# EFM32ZG1xx_2xx register map
File version: 2.7.3
CPU: CM0PLUS r0p1, little endian, no MPU, no FPU, 3 interrupt priority bits
Registers are 32-bit, read-write, reset 0x0 unless marked. A register's access mark holds for its fields unless they carry their own. Offsets are from the block's base; [hi:lo] are bit positions; {n}, {i} and the like mark numbered series.

## DMA
Base 0x400C2000
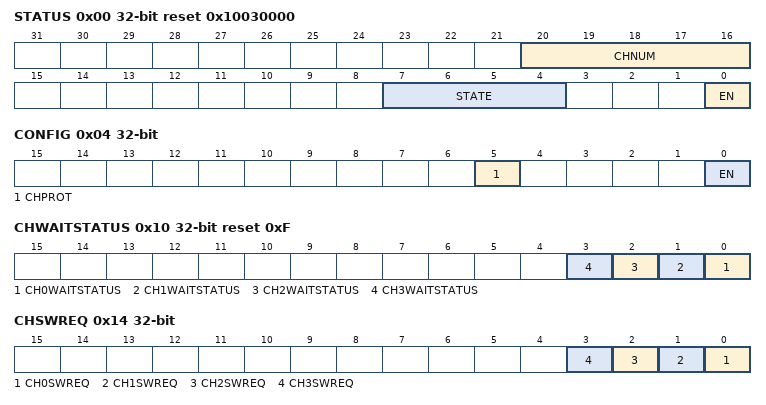
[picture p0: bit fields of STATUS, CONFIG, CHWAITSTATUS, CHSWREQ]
0x00 STATUS ro reset 0x10030000 — DMA Status Registers
  [20:16] CHNUM — Channel Number
  [7:4] STATE — Control Current State
    0=IDLE; 1=RDCHCTRLDATA (Reading channel controller data); 2=RDSRCENDPTR (Reading source data end pointer); 3=RDDSTENDPTR (Reading destination data end pointer); 4=RDSRCDATA (Reading source data); 5=WRDSTDATA (Writing destination data); 6=WAITREQCLR (Waiting for DMA request to clear); 7=WRCHCTRLDATA (Writing channel controller data); 8=STALLED; 9=DONE; 10=PERSCATTRANS (Peripheral scatter-gather transition)
  [0] EN — DMA Enable Status
0x04 CONFIG wo — DMA Configuration Register
  [5] CHPROT — Channel Protection Control
  [0] EN — Enable DMA
0x08 CTRLBASE — Channel Control Data Base Pointer Register
  [31:0] CTRLBASE — Channel Control Data Base Pointer
0x0C ALTCTRLBASE ro reset 0x40 — Channel Alternate Control Data Base Pointer Register
  [31:0] ALTCTRLBASE — Channel Alternate Control Data Base Pointer
0x10 CHWAITSTATUS ro reset 0xF — Channel Wait on Request Status Register
  [n] CH{n}WAITSTATUS (n=0..3) — Channel {n} Wait on Request Status
0x14 CHSWREQ wo — Channel Software Request Register
  [n] CH{n}SWREQ (n=0..3) — Channel {n} Software Request
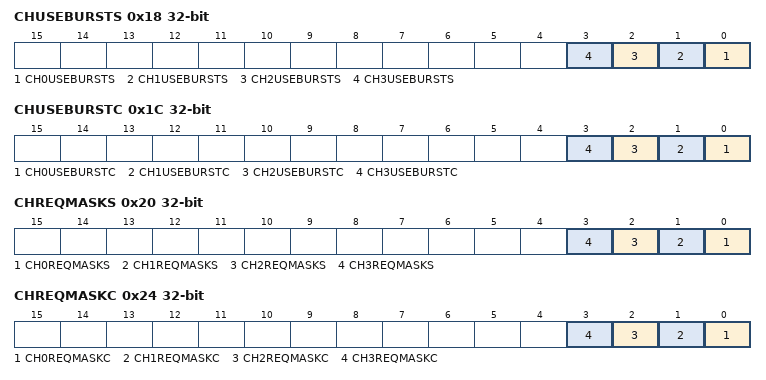
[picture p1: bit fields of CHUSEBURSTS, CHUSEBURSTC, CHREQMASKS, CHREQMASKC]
0x18 CHUSEBURSTS — Channel Useburst Set Register
  [n] CH{n}USEBURSTS (n=0..3) — Channel {n} Useburst Set
0x1C CHUSEBURSTC wo — Channel Useburst Clear Register
  [n] CH{n}USEBURSTC (n=0..3) — Channel {n} Useburst Clear
0x20 CHREQMASKS wo — Channel Request Mask Set Register
  [n] CH{n}REQMASKS (n=0..3) — Channel {n} Request Mask Set
0x24 CHREQMASKC wo — Channel Request Mask Clear Register
  [n] CH{n}REQMASKC (n=0..3) — Channel {n} Request Mask Clear
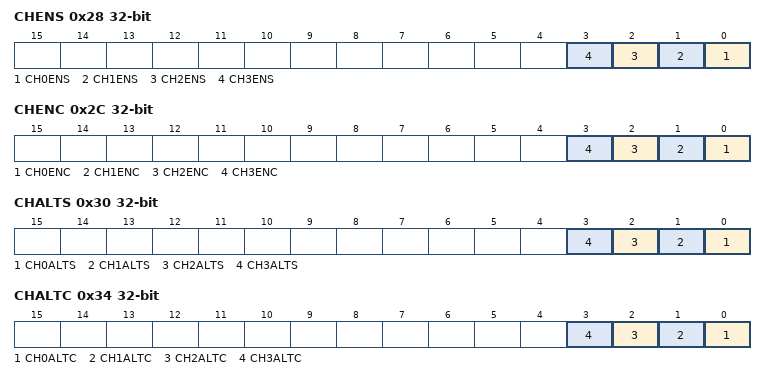
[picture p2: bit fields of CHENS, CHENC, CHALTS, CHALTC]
0x28 CHENS wo — Channel Enable Set Register
  [n] CH{n}ENS (n=0..3) — Channel {n} Enable Set
0x2C CHENC wo — Channel Enable Clear Register
  [n] CH{n}ENC (n=0..3) — Channel {n} Enable Clear
0x30 CHALTS wo — Channel Alternate Set Register
  [n] CH{n}ALTS (n=0..3) — Channel {n} Alternate Structure Set
0x34 CHALTC wo — Channel Alternate Clear Register
  [n] CH{n}ALTC (n=0..3) — Channel {n} Alternate Clear
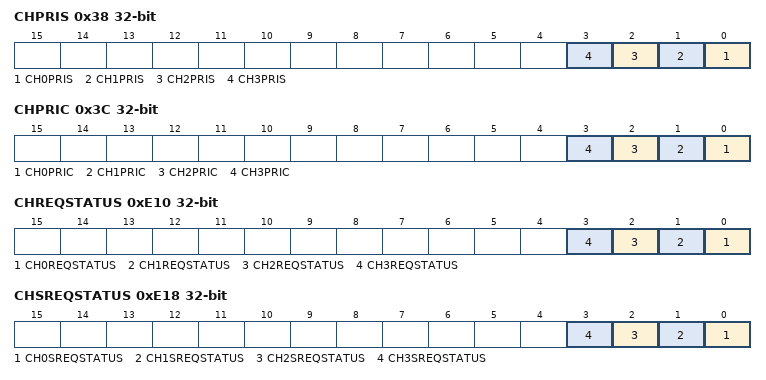
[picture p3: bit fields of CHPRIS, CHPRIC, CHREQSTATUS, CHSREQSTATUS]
0x38 CHPRIS wo — Channel Priority Set Register
  [n] CH{n}PRIS (n=0..3) — Channel {n} High Priority Set
0x3C CHPRIC wo — Channel Priority Clear Register
  [n] CH{n}PRIC (n=0..3) — Channel {n} High Priority Clear
0x4C ERRORC — Bus Error Clear Register
  [0] ERRORC — Bus Error Clear
0xE10 CHREQSTATUS ro — Channel Request Status
  [n] CH{n}REQSTATUS (n=0..3) — Channel {n} Request Status
0xE18 CHSREQSTATUS ro — Channel Single Request Status
  [n] CH{n}SREQSTATUS (n=0..3) — Channel {n} Single Request Status
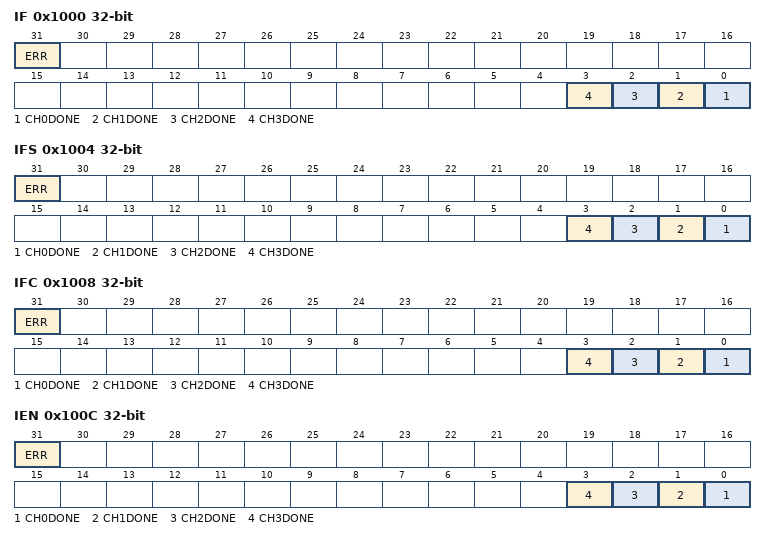
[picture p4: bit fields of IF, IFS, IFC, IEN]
0x1000 IF ro — Interrupt Flag Register
  [31] ERR — DMA Error Interrupt Flag
  [n] CH{n}DONE (n=0..3) — DMA Channel {n} Complete Interrupt Flag
0x1004 IFS wo — Interrupt Flag Set Register
  [31] ERR — DMA Error Interrupt Flag Set
  [n] CH{n}DONE (n=0..3) — DMA Channel {n} Complete Interrupt Flag Set
0x1008 IFC wo — Interrupt Flag Clear Register
  [31] ERR — DMA Error Interrupt Flag Clear
  [n] CH{n}DONE (n=0..3) — DMA Channel {n} Complete Interrupt Flag Clear
0x100C IEN — Interrupt Enable register
  [31] ERR — DMA Error Interrupt Flag Enable
  [n] CH{n}DONE (n=0..3) — DMA Channel {n} Complete Interrupt Enable
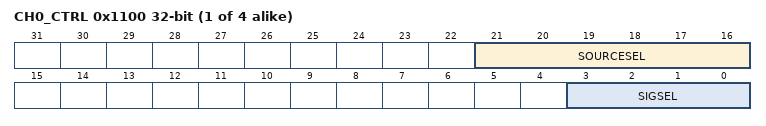
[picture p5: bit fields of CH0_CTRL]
{0x1100+4i} CH{i}_CTRL (i=0..3) — Channel Control Register
  [21:16] SOURCESEL — Source Select
    0=NONE (No source selected); 8=ADC0 (Analog to Digital Converter 0); 13=USART1 (Universal Synchronous/Asynchronous Receiver/Transmitter 1); 16=LEUART0 (Low Energy UART 0); 20=I2C0; 24=TIMER0; 25=TIMER1; 48=MSC; 49=AES (Advanced Encryption Standard Accelerator)
  [3:0] SIGSEL — Signal Select

## MSC
Base 0x400C0000
0x00 CTRL reset 0x1 — Memory System Control Register
  [0] BUSFAULT — Bus Fault Response Enable
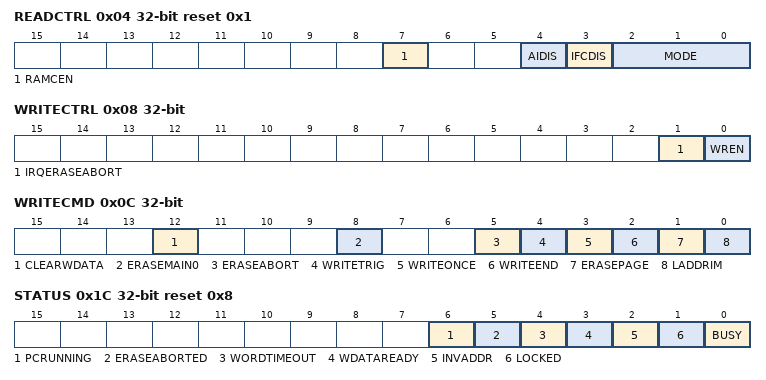
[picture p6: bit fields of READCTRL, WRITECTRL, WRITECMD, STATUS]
0x04 READCTRL reset 0x1 — Read Control Register
  [7] RAMCEN — RAM Cache Enable
  [4] AIDIS — Automatic Invalidate Disable
  [3] IFCDIS — Internal Flash Cache Disable
  [2:0] MODE — Read Mode
    0=WS0 (Zero wait-states inserted in fetch or read transfers.); 1=WS1 (One wait-state inserted for each fetch or read transfer. This mode is required for a core frequency above 16 MHz.)
0x08 WRITECTRL — Write Control Register
  [1] IRQERASEABORT — Abort Page Erase on Interrupt
  [0] WREN — Enable Write/Erase Controller
0x0C WRITECMD wo — Write Command Register
  [12] CLEARWDATA — Clear WDATA state
  [8] ERASEMAIN0 — Mass erase region 0
  [5] ERASEABORT — Abort erase sequence
  [4] WRITETRIG — Word Write Sequence Trigger
  [3] WRITEONCE — Word Write-Once Trigger
  [2] WRITEEND — End Write Mode
  [1] ERASEPAGE
  [0] LADDRIM — Load MSC_ADDRB into ADDR
0x10 ADDRB — Page Erase/Write Address Buffer
  [31:0] ADDRB — Page Erase or Write Address Buffer
0x18 WDATA — Write Data Register
  [31:0] WDATA — Write Data
0x1C STATUS ro reset 0x8
  [6] PCRUNNING — Performance Counters Running
  [5] ERASEABORTED — The Current Flash Erase Operation Aborted
  [4] WORDTIMEOUT — Flash Write Word Timeout
  [3] WDATAREADY — WDATA Write Ready
  [2] INVADDR — Invalid Write Address or Erase Page
  [1] LOCKED — Access Locked
  [0] BUSY — Erase/Write Busy
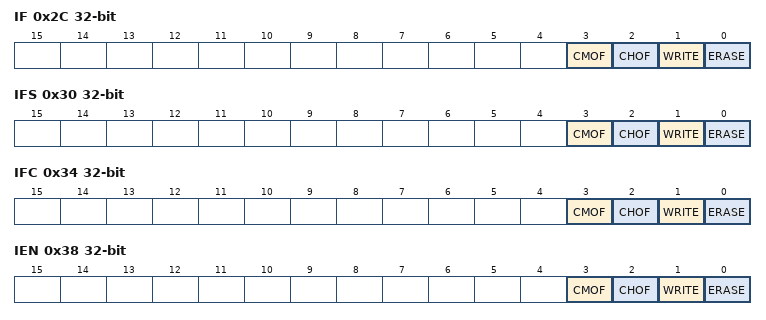
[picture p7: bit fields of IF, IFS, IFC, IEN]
0x2C IF ro — Interrupt Flag Register
  [3] CMOF — Cache Misses Overflow Interrupt Flag
  [2] CHOF — Cache Hits Overflow Interrupt Flag
  [1] WRITE — Write Done Interrupt Read Flag
  [0] ERASE — Erase Done Interrupt Read Flag
0x30 IFS wo — Interrupt Flag Set Register
  [3] CMOF — Cache Misses Overflow Interrupt Set
  [2] CHOF — Cache Hits Overflow Interrupt Set
  [1] WRITE — Write Done Interrupt Set
  [0] ERASE — Erase Done Interrupt Set
0x34 IFC wo — Interrupt Flag Clear Register
  [3] CMOF — Cache Misses Overflow Interrupt Clear
  [2] CHOF — Cache Hits Overflow Interrupt Clear
  [1] WRITE — Write Done Interrupt Clear
  [0] ERASE — Erase Done Interrupt Clear
0x38 IEN — Interrupt Enable Register
  [3] CMOF — Cache Misses Overflow Interrupt Enable
  [2] CHOF — Cache Hits Overflow Interrupt Enable
  [1] WRITE — Write Done Interrupt Enable
  [0] ERASE — Erase Done Interrupt Enable
0x3C LOCK — Configuration Lock Register
  [15:0] LOCKKEY — Configuration Lock
    0=UNLOCKED; 1=LOCKED
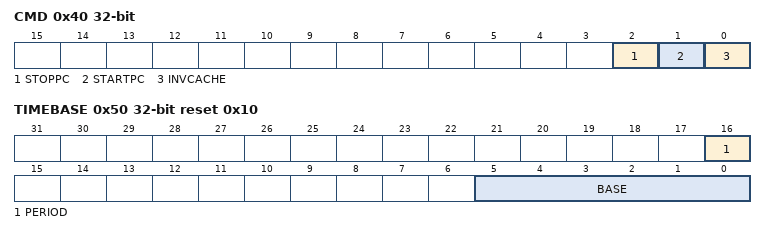
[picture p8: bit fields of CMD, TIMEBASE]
0x40 CMD wo — Command Register
  [2] STOPPC — Stop Performance Counters
  [1] STARTPC — Start Performance Counters
  [0] INVCACHE — Invalidate Instruction Cache
0x44 CACHEHITS ro — Cache Hits Performance Counter
  [19:0] CACHEHITS — Cache hits since last performance counter start command.
0x48 CACHEMISSES ro — Cache Misses Performance Counter
  [19:0] CACHEMISSES — Cache misses since last performance counter start command.
0x50 TIMEBASE reset 0x10 — Flash Write and Erase Timebase
  [16] PERIOD — Sets the timebase period
  [5:0] BASE — Timebase used by MSC to time flash writes and erases
0x54 MASSLOCK reset 0x1 — Mass Erase Lock Register
  [15:0] LOCKKEY — Mass Erase Lock
    0=UNLOCKED (Mass erase unlocked.); 1=LOCKED (Mass erase locked.)
0x58 IRQLATENCY
  [7:0] IRQLATENCY

## Notices in the file
# License
Copyright 2020 Silicon Laboratories Inc. www.silabs.com
SPDX-License-Identifier: Zlib
The licensor of this software is Silicon Laboratories Inc.
This software is provided 'as-is', without any express or implied
warranty. In no event will the authors be held liable for any damages
arising from the use of this software.
Permission is granted to anyone to use this software for any purpose,
including commercial applications, and to alter it and redistribute it
freely, subject to the following restrictions:
1. The origin of this software must not be misrepresented; you must not
claim that you wrote the original software. If you use this software
in a product, an acknowledgment in the product documentation would be
appreciated but is not required.
2. Altered source versions must be plainly marked as such, and must not be
misrepresented as being the original software.
3. This notice may not be removed or altered from any source distribution.
